# PIC32MZ2048EFM144 register map
Vendor: Microchip
Registers are 32-bit, read-write, reset 0x0 unless marked. A register's access mark holds for its fields unless they carry their own. Addresses are absolute, and some are shared; only a register's first bit layout is shown; [hi:lo] are bit positions; {n}, {i} and the like mark numbered series.

## OCMP3
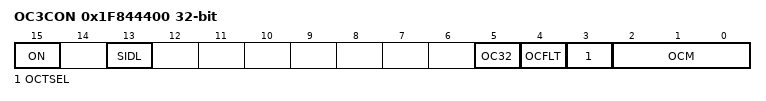
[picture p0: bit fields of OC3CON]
0x1F844400 OC3CON
  [15] ON, [13] SIDL, [5] OC32, [4] OCFLT ro, [3] OCTSEL, [2:0] OCM
0x1F844410 OC3R reset not defined — (power-on value xxxxxxxxxxxxxxxxxxxxxxxxxxxxxxxx)
0x1F844420 OC3RS reset not defined — (power-on value xxxxxxxxxxxxxxxxxxxxxxxxxxxxxxxx)

## OCMP4
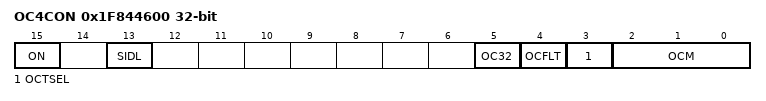
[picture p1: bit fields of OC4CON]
0x1F844600 OC4CON
  [15] ON, [13] SIDL, [5] OC32, [4] OCFLT ro, [3] OCTSEL, [2:0] OCM
0x1F844610 OC4R reset not defined — (power-on value xxxxxxxxxxxxxxxxxxxxxxxxxxxxxxxx)
0x1F844620 OC4RS reset not defined — (power-on value xxxxxxxxxxxxxxxxxxxxxxxxxxxxxxxx)

## OCMP5
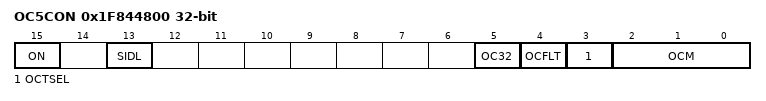
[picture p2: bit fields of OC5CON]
0x1F844800 OC5CON
  [15] ON, [13] SIDL, [5] OC32, [4] OCFLT ro, [3] OCTSEL, [2:0] OCM
0x1F844810 OC5R reset not defined — (power-on value xxxxxxxxxxxxxxxxxxxxxxxxxxxxxxxx)
0x1F844820 OC5RS reset not defined — (power-on value xxxxxxxxxxxxxxxxxxxxxxxxxxxxxxxx)

## OCMP6
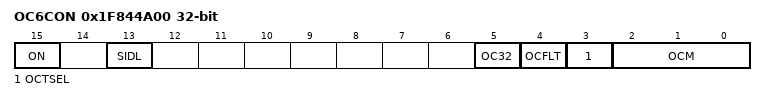
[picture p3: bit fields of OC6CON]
0x1F844A00 OC6CON
  [15] ON, [13] SIDL, [5] OC32, [4] OCFLT ro, [3] OCTSEL, [2:0] OCM
0x1F844A10 OC6R reset not defined — (power-on value xxxxxxxxxxxxxxxxxxxxxxxxxxxxxxxx)
0x1F844A20 OC6RS reset not defined — (power-on value xxxxxxxxxxxxxxxxxxxxxxxxxxxxxxxx)

## OCMP7
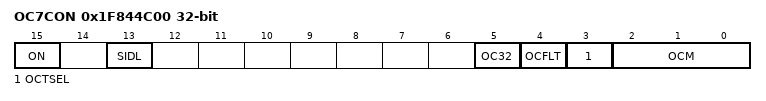
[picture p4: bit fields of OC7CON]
0x1F844C00 OC7CON
  [15] ON, [13] SIDL, [5] OC32, [4] OCFLT ro, [3] OCTSEL, [2:0] OCM
0x1F844C10 OC7R reset not defined — (power-on value xxxxxxxxxxxxxxxxxxxxxxxxxxxxxxxx)
0x1F844C20 OC7RS reset not defined — (power-on value xxxxxxxxxxxxxxxxxxxxxxxxxxxxxxxx)

## OCMP8
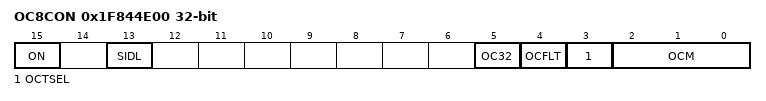
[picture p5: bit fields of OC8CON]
0x1F844E00 OC8CON
  [15] ON, [13] SIDL, [5] OC32, [4] OCFLT ro, [3] OCTSEL, [2:0] OCM
0x1F844E10 OC8R reset not defined — (power-on value xxxxxxxxxxxxxxxxxxxxxxxxxxxxxxxx)
0x1F844E20 OC8RS reset not defined — (power-on value xxxxxxxxxxxxxxxxxxxxxxxxxxxxxxxx)

## OCMP9
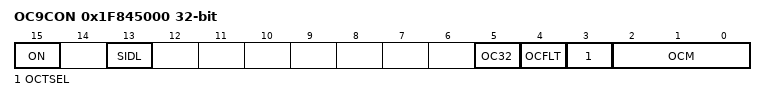
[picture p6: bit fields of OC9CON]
0x1F845000 OC9CON
  [15] ON, [13] SIDL, [5] OC32, [4] OCFLT ro, [3] OCTSEL, [2:0] OCM
0x1F845010 OC9R reset not defined — (power-on value xxxxxxxxxxxxxxxxxxxxxxxxxxxxxxxx)
0x1F845020 OC9RS reset not defined — (power-on value xxxxxxxxxxxxxxxxxxxxxxxxxxxxxxxx)

## ADCHS
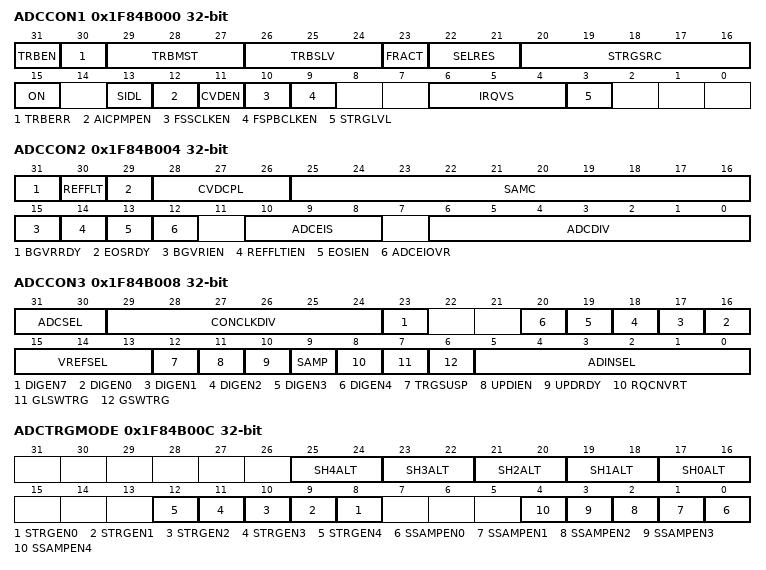
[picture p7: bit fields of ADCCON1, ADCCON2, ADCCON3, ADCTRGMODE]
0x1F84B000 ADCCON1
  [31] TRBEN, [30] TRBERR ro, [29:27] TRBMST, [26:24] TRBSLV, [23] FRACT, [22:21] SELRES, [20:16] STRGSRC, [15] ON, [13] SIDL, [12] AICPMPEN, [11] CVDEN, [10] FSSCLKEN, [9] FSPBCLKEN, [6:4] IRQVS, [3] STRGLVL
0x1F84B004 ADCCON2
  [31] BGVRRDY ro, [30] REFFLT ro, [29] EOSRDY ro, [28:26] CVDCPL, [25:16] SAMC, [15] BGVRIEN, [14] REFFLTIEN, [13] EOSIEN, [12] ADCEIOVR, [10:8] ADCEIS, [6:0] ADCDIV
0x1F84B008 ADCCON3
  [31:30] ADCSEL, [29:24] CONCLKDIV, [23] DIGEN7 ro, [n+16] DIGEN{n} ro (n=0..4), [15:13] VREFSEL, [12] TRGSUSP, [11] UPDIEN, [10] UPDRDY, [9] SAMP, [8] RQCNVRT, [7] GLSWTRG, [6] GSWTRG, [5:0] ADINSEL
0x1F84B00C ADCTRGMODE
  [2n+17:2n+16] SH{n}ALT (n=0..4), [n+8] STRGEN{n} (n=0..4), [n] SSAMPEN{n} (n=0..4)
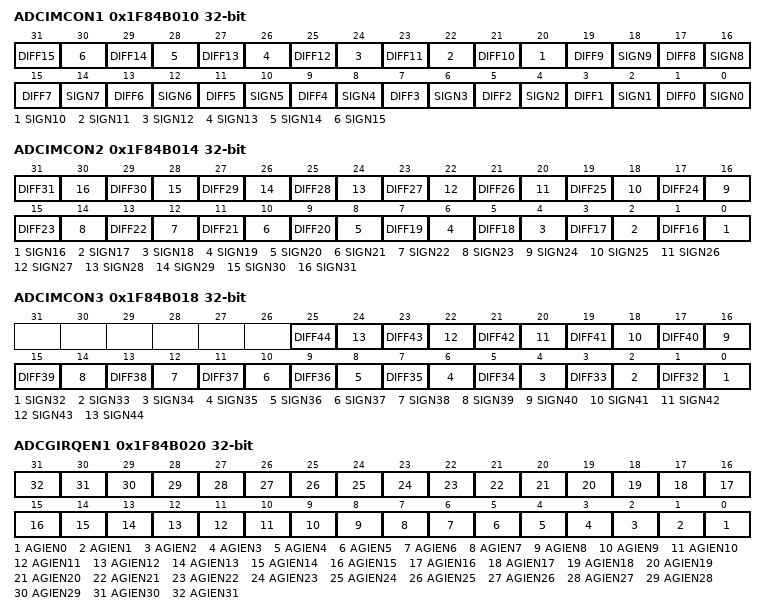
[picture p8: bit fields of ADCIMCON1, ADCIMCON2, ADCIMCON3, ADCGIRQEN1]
0x1F84B010 ADCIMCON1
  [2n+1] DIFF{n} (n=0..15), [2n] SIGN{n} (n=0..15)
0x1F84B014 ADCIMCON2
  [2n-31] DIFF{n} (n=16..31), [2n-32] SIGN{n} (n=16..31)
0x1F84B018 ADCIMCON3
  [2n-63] DIFF{n} (n=32..44), [2n-64] SIGN{n} (n=32..44)
0x1F84B020 ADCGIRQEN1
  [n] AGIEN{n} (n=0..31)
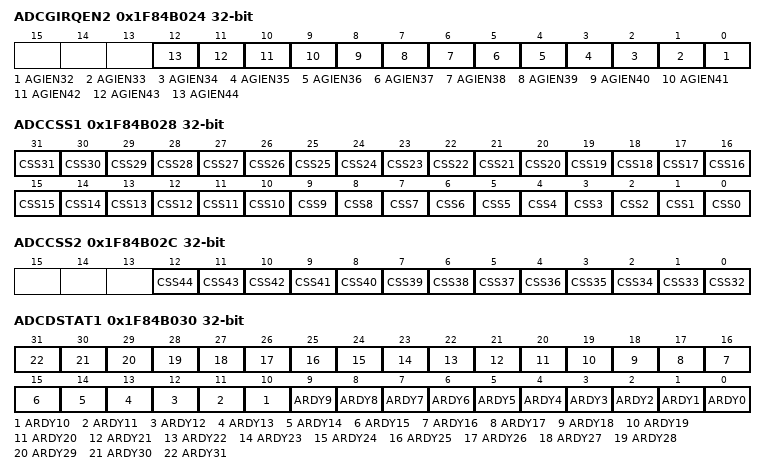
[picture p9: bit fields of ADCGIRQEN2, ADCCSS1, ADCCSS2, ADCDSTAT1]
0x1F84B024 ADCGIRQEN2
  [n-32] AGIEN{n} (n=32..44)
0x1F84B028 ADCCSS1
  [n] CSS{n} (n=0..31)
0x1F84B02C ADCCSS2
  [n-32] CSS{n} (n=32..44)
0x1F84B030 ADCDSTAT1 ro
  [n] ARDY{n} (n=0..31)
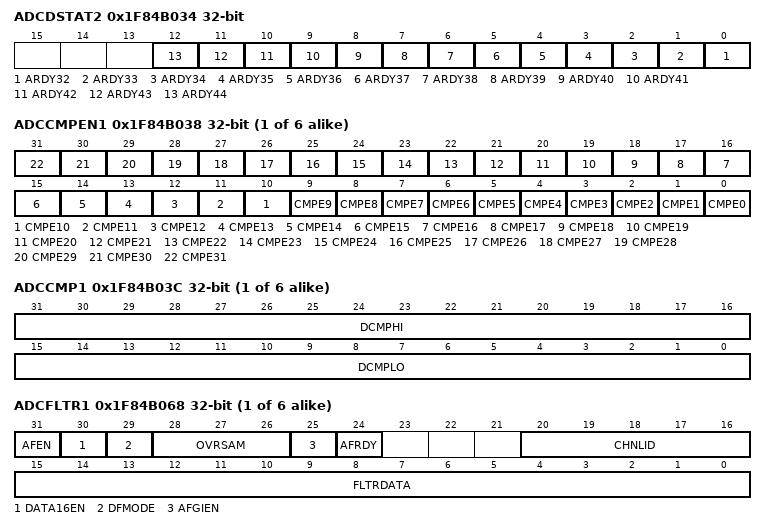
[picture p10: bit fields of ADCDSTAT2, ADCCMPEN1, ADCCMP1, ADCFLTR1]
0x1F84B034 ADCDSTAT2 ro
  [n-32] ARDY{n} (n=32..44)
{0x1F84B030+8i} ADCCMPEN{i} (i=1..6)
  [n] CMPE{n} (n=0..31)
{0x1F84B034+8i} ADCCMP{i} (i=1..6)
  [31:16] DCMPHI, [15:0] DCMPLO
{0x1F84B064+4i} ADCFLTR{i} (i=1..6)
  [31] AFEN, [30] DATA16EN, [29] DFMODE, [28:26] OVRSAM, [25] AFGIEN, [24] AFRDY ro, [20:16] CHNLID, [15:0] FLTRDATA ro
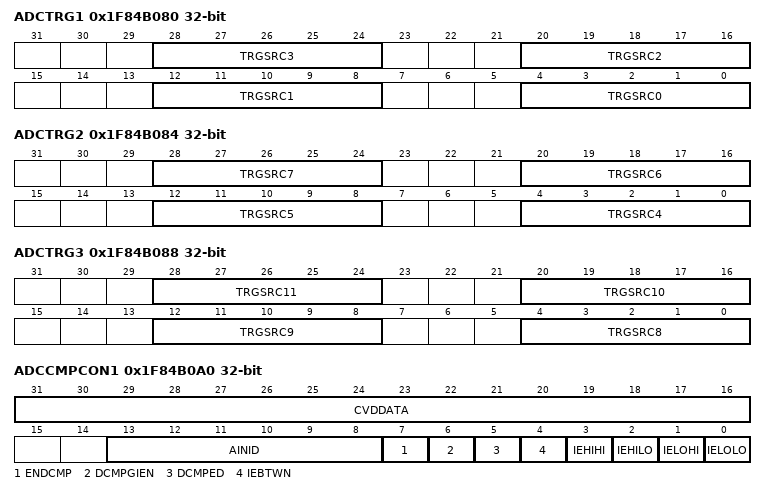
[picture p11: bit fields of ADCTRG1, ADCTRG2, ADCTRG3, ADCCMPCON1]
0x1F84B080 ADCTRG1
  [8n+4:8n] TRGSRC{n} (n=0..3)
0x1F84B084 ADCTRG2
  [8n-28:8n-32] TRGSRC{n} (n=4..7)
0x1F84B088 ADCTRG3
  [8n-60:8n-64] TRGSRC{n} (n=8..11)
0x1F84B0A0 ADCCMPCON1
  [31:16] CVDDATA ro, [13:8] AINID ro, [7] ENDCMP, [6] DCMPGIEN, [5] DCMPED ro, [4] IEBTWN, [3] IEHIHI, [2] IEHILO, [1] IELOHI, [0] IELOLO
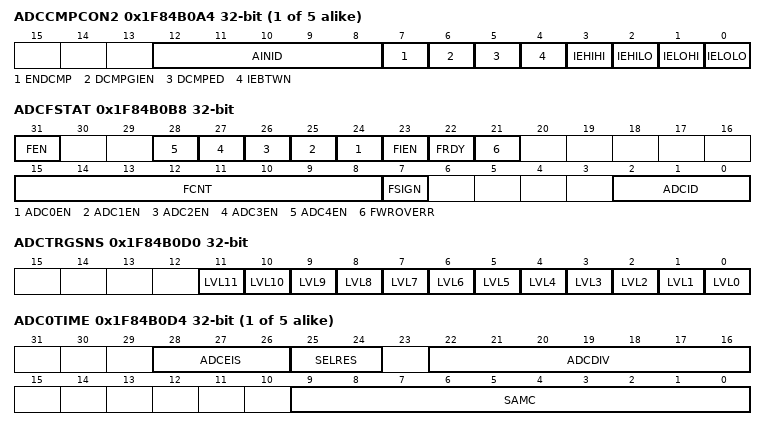
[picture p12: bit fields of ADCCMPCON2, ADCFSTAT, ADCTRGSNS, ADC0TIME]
{0x1F84B09C+4i} ADCCMPCON{i} (i=2..6)
  [12:8] AINID ro, [7] ENDCMP, [6] DCMPGIEN, [5] DCMPED ro, [4] IEBTWN, [3] IEHIHI, [2] IEHILO, [1] IELOHI, [0] IELOLO
0x1F84B0B8 ADCFSTAT
  [31] FEN, [n+24] ADC{n}EN (n=0..4), [23] FIEN, [22] FRDY ro, [21] FWROVERR ro, [15:8] FCNT ro, [7] FSIGN ro, [2:0] ADCID
0x1F84B0BC ADCFIFO ro
  [31:0] DATA
0x1F84B0C0 ADCBASE
  [15:0] ADCBASE
0x1F84B0D0 ADCTRGSNS
  [n] LVL{n} (n=0..11)
{0x1F84B0D4+4i} ADC{i}TIME (i=0..4)
  [28:26] ADCEIS, [25:24] SELRES, [22:16] ADCDIV, [9:0] SAMC
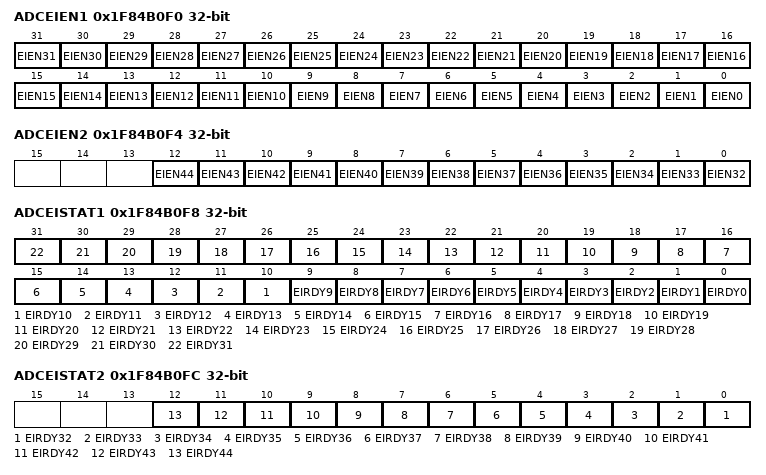
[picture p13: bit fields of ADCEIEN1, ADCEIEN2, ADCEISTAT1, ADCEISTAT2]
0x1F84B0F0 ADCEIEN1
  [n] EIEN{n} (n=0..31)
0x1F84B0F4 ADCEIEN2
  [n-32] EIEN{n} (n=32..44)
0x1F84B0F8 ADCEISTAT1 ro
  [n] EIRDY{n} (n=0..31)
0x1F84B0FC ADCEISTAT2 ro
  [n-32] EIRDY{n} (n=32..44)
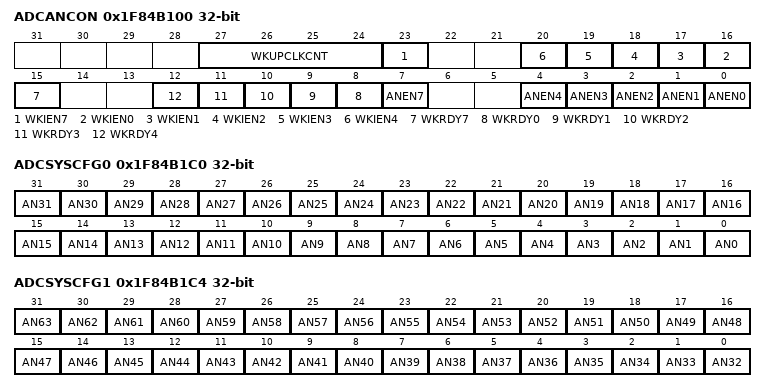
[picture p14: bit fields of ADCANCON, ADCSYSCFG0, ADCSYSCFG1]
0x1F84B100 ADCANCON
  [27:24] WKUPCLKCNT, [23] WKIEN7, [n+16] WKIEN{n} (n=0..4), [15] WKRDY7 ro, [n+8] WKRDY{n} ro (n=0..4), [7] ANEN7, [n] ANEN{n} (n=0..4)
{0x1F84B180+4i} ADC{i}CFG (i=0..4)
  [31:0] ADCCFG
0x1F84B19C ADC7CFG
  [31:0] ADCCFG
0x1F84B1C0 ADCSYSCFG0 ro
  [n] AN{n} (n=0..31)
0x1F84B1C4 ADCSYSCFG1 ro
  [n-32] AN{n} (n=32..63)
{0x1F84B200+4i} ADCDATA{i} (i=0..44)
  [31:0] DATA
